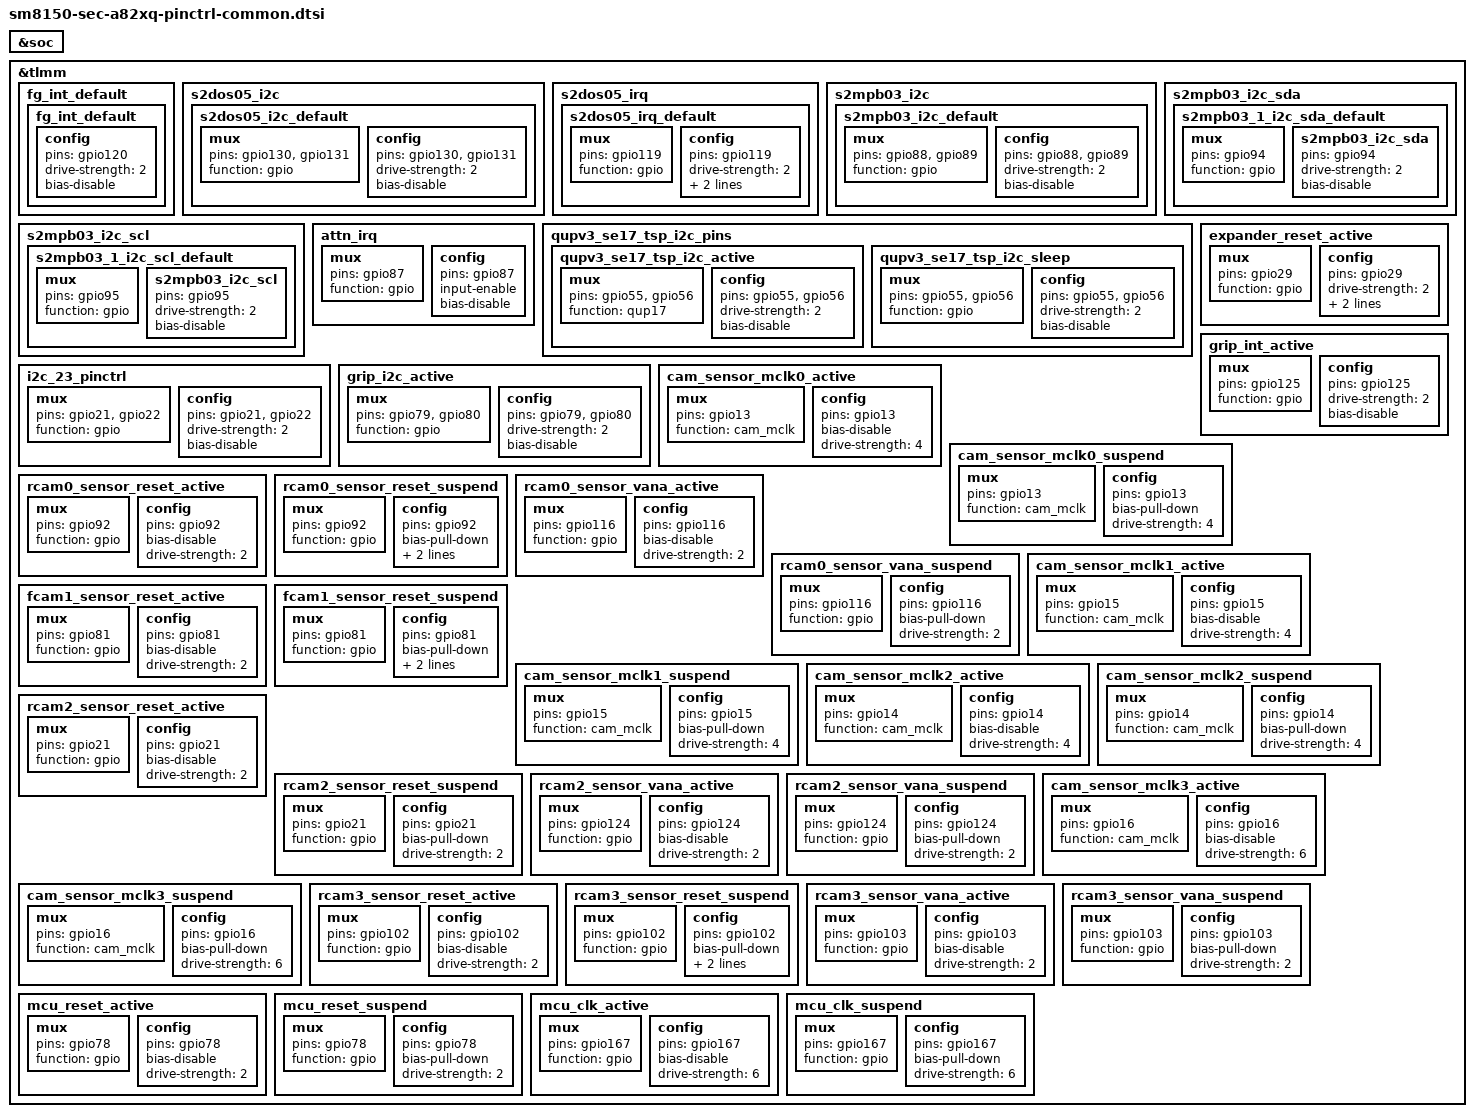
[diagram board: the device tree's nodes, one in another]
/* Copyright (c) 2016-2018, The Linux Foundation. All rights reserved.
 *
 * This program is free software; you can redistribute it and/or modify
 * it under the terms of the GNU General Public License version 2 and
 * only version 2 as published by the Free Software Foundation.
 *
 * This program is distributed in the hope that it will be useful,
 * but WITHOUT ANY WARRANTY; without even the implied warranty of
 * MERCHANTABILITY or FITNESS FOR A PARTICULAR PURPOSE.  See the
 * GNU General Public License for more details.
 */

&soc {
};

&tlmm {
	fg_int_default {
		fg_int_default: fg_int_default {
			config {
				pins = "gpio120";
				drive-strength = <2>;
				bias-disable;
			};
		};
	};

	s2dos05_i2c {
		s2dos05_i2c_default: s2dos05_i2c_default {
			mux {
				pins = "gpio130", "gpio131";
				function = "gpio";
			};

			config {
				pins = "gpio130", "gpio131";
				drive-strength = <2>;
				bias-disable;
			};
		};
	};

	s2dos05_irq {
		s2dos05_irq_default: s2dos05_irq_default {
			mux {
				pins = "gpio119";
				function = "gpio";
			};

			config {
				pins = "gpio119";
				drive-strength = <2>;
				bias-disable;
				input-enable;
			};
		};
	};

	s2mpb03_i2c {
		s2mpb03_i2c_default: s2mpb03_i2c_default {
			mux {
				pins = "gpio88", "gpio89";
				function = "gpio";
			};

			config {
				pins = "gpio88", "gpio89";
				drive-strength = <2>;
				bias-disable;
			};
		};
	};

	s2mpb03_i2c_sda {
		s2mpb03_1_i2c_sda_default: s2mpb03_1_i2c_sda_default {
			mux {
				pins = "gpio94";
				function = "gpio";
			};
			s2mpb03_i2c_sda {
				pins = "gpio94";
				drive-strength = <2>;
				bias-disable;
			};
		};
	};

	s2mpb03_i2c_scl {
		s2mpb03_1_i2c_scl_default: s2mpb03_1_i2c_scl_default {
			mux {
				pins = "gpio95";
				function = "gpio";
			};
			s2mpb03_i2c_scl {
				pins = "gpio95";
				drive-strength = <2>;
				bias-disable;
			};
		};
	};

	attn_irq: attn_irq {
		mux {
			pins = "gpio87";
			function = "gpio";
		};
		config {
			pins = "gpio87";
			input-enable;
			bias-disable;
		};
	};

#if 0
	muic_i2c {
		muic_i2c_active: muic_i2c_active {
			muic_i2c {
				pins = "gpio25", "gpio26";
				drive-strength = <2>;
				bias-disable;
			};
		};
		muic_i2c_suspend: muic_i2c_suspend {
			muic_i2c {
				pins = "gpio25", "gpio26";
				drive-strength = <2>;
				bias-disable;
			};
		};
	};
#endif
	/* SE 17 pin mappings */
	qupv3_se17_tsp_i2c_pins: qupv3_se17_tsp_i2c_pins {
		qupv3_se17_tsp_i2c_active: qupv3_se17_tsp_i2c_active {
			mux {
				pins = "gpio55", "gpio56";
				function = "qup17";
			};

			config {
				pins = "gpio55", "gpio56";
				drive-strength = <2>;
				bias-disable;
			};
		};

		qupv3_se17_tsp_i2c_sleep: qupv3_se17_tsp_i2c_sleep {
			mux {
				pins = "gpio55", "gpio56";
				function = "gpio";
			};

			config {
				pins = "gpio55", "gpio56";
				drive-strength = <2>;
				bias-disable;
			};
		};
	};

	i2c_23_pinctrl: i2c_23_pinctrl {
		mux {
			pins = "gpio21",	/* EXPANDER_I2C_SDA_1P8 */
			       "gpio22";	/* EXPANDER_I2C_SCL_1P8 */
			function = "gpio";
		};
		config {
			pins = "gpio21",	/* EXPANDER_I2C_SDA_1P8 */
			       "gpio22";	/* EXPANDER_I2C_SCL_1P8 */
			drive-strength = <2>;
			bias-disable;
		};
	};

	expander_reset_active: expander_reset_active {
		mux {
			pins = "gpio29";
			function = "gpio";
		};
		config {
			pins = "gpio29";
			drive-strength = <2>;   /* 16 mA */
			bias-disable;
			output-high;
		};
	};

	grip_i2c_active: grip_i2c_active {
		mux {
			pins = "gpio79", "gpio80";
			function = "gpio";
		};
		config {
			pins = "gpio79", "gpio80";
			drive-strength = <2>;
			bias-disable;
		};
	};

	grip_int_active: grip_int_active {
		mux {
			pins = "gpio125";
			function = "gpio";
		};
		config {
			pins = "gpio125";
			drive-strength = <2>;
			bias-disable;
		};
	};

	cam_sensor_mclk0_active: cam_sensor_mclk0_active {
        /* MCLK0 */
        mux {
            pins = "gpio13";
            function = "cam_mclk";
        };
        config {
            pins = "gpio13";
            bias-disable; /* No PULL */
            drive-strength = <4>; /* 4 MA */
        };
    };

    cam_sensor_mclk0_suspend: cam_sensor_mclk0_suspend {
        /* MCLK0 */
        mux {
            pins = "gpio13";
            function = "cam_mclk";
        };
        config {
            pins = "gpio13";
            bias-pull-down; /* PULL DOWN */
            drive-strength = <4>; /* 4 MA */
        };
    };

    rcam0_sensor_reset_active: rcam0_sensor_reset_active {
        /* RESET REAR */
        mux {
            pins = "gpio92";
            function = "gpio";
        };
        config {
            pins = "gpio92";
            bias-disable; /* No PULL */
            drive-strength = <2>; /* 2 MA */
        };
    };

    rcam0_sensor_reset_suspend: rcam0_sensor_reset_suspend {
        /* RESET REAR */
        mux {
            pins = "gpio92";
            function = "gpio";
        };
        config {
            pins = "gpio92";
            bias-pull-down; /* PULL DOWN */
            drive-strength = <2>; /* 2 MA */
            output-low;
        };
    };

    rcam0_sensor_vana_active: rcam0_sensor_vana_active {
        /* Rear VANA */
        mux {
            pins = "gpio116";
            function = "gpio";
        };
        config {
            pins = "gpio116";
            bias-disable; /* No PULL */
            drive-strength = <2>; /* 2 MA */
        };
    };

    rcam0_sensor_vana_suspend: rcam0_sensor_vana_suspend {
        /* Rear VANA */
        mux {
            pins = "gpio116";
            function = "gpio";
        };
        config {
            pins = "gpio116";
            bias-pull-down; /* PULL DOWN */
            drive-strength = <2>; /* 2 MA */
        };
    };
	
    cam_sensor_mclk1_active: cam_sensor_mclk1_active {
        /* MCLK1 */
        mux {
            pins = "gpio15";
            function = "cam_mclk";
        };
        config {
            pins = "gpio15";
            bias-disable; /* No PULL */
            drive-strength = <4>; /* 4 MA */
        };
    };

    fcam1_sensor_reset_active: fcam1_sensor_reset_active {
        /* RESET FRONT */
        mux {
            pins = "gpio81";
            function = "gpio";
        };

        config {
            pins = "gpio81";
            bias-disable; /* No PULL */
            drive-strength = <2>; /* 2 MA */
        };
    };

    fcam1_sensor_reset_suspend: fcam1_sensor_reset_suspend {
        /* RESET FRONT */
        mux {
            pins = "gpio81";
            function = "gpio";
        };

        config {
            pins = "gpio81";
            bias-pull-down; /* PULL DOWN */
            drive-strength = <2>; /* 2 MA */
            output-low;
        };
    };

    cam_sensor_mclk1_suspend: cam_sensor_mclk1_suspend {
        /* MCLK1 */
        mux {
            pins = "gpio15";
            function = "cam_mclk";
        };
        config {
            pins = "gpio15";
            bias-pull-down; /* PULL DOWN */
            drive-strength = <4>; /* 4 MA */
        };
    };

    cam_sensor_mclk2_active: cam_sensor_mclk2_active {
        /* MCLK2 */
        mux {
            pins = "gpio14";
            function = "cam_mclk";
        };

        config {
            pins = "gpio14";
            bias-disable; /* No PULL */
            drive-strength = <4>; /* 4 MA */
        };
    };

    cam_sensor_mclk2_suspend: cam_sensor_mclk2_suspend {
        /* MCLK2 */
        mux {
            pins = "gpio14";
            function = "cam_mclk";
        };

        config {
            pins = "gpio14";
            bias-pull-down; /* PULL DOWN */
            drive-strength = <4>; /* 4 MA */
        };
    };

    rcam2_sensor_reset_active: rcam2_sensor_reset_active {
        /* UW RESET */
        mux {
            pins = "gpio21";
            function = "gpio";
        };
        config {
            pins = "gpio21";
            bias-disable; /* No PULL */
            drive-strength = <2>; /* 2 MA */
        };
    };

    rcam2_sensor_reset_suspend: rcam2_sensor_reset_suspend {
        /* UW RESET */
        mux {
            pins = "gpio21";
            function = "gpio";
        };
        config {
            pins = "gpio21";
            bias-pull-down; /* PULL DOWN */
            drive-strength = <2>; /* 2 MA */
        };
    };

    rcam2_sensor_vana_active: rcam2_sensor_vana_active {
        /* UW VANA */
        mux {
            pins = "gpio124";
            function = "gpio";
        };
        config {
            pins = "gpio124";
            bias-disable; /* No PULL */
            drive-strength = <2>; /* 2 MA */
        };
    };

    rcam2_sensor_vana_suspend: rcam2_sensor_vana_suspend {
        /* UW VANA */
        mux {
            pins = "gpio124";
            function = "gpio";
        };
        config {
            pins = "gpio124";
            bias-pull-down; /* PULL DOWN */
            drive-strength = <2>; /* 2 MA */
        };
    };

    cam_sensor_mclk3_active: cam_sensor_mclk3_active {
        /* MCLK3 */
        mux {
            pins = "gpio16";
            function = "cam_mclk";
        };

        config {
            pins = "gpio16";
            bias-disable; /* No PULL */
            drive-strength = <6>; /* 6 MA */
        };
    };

    cam_sensor_mclk3_suspend: cam_sensor_mclk3_suspend {
        /* MCLK3 */
        mux {
            pins = "gpio16";
            function = "cam_mclk";
        };

        config {
            pins = "gpio16";
            bias-pull-down; /* PULL DOWN */
            drive-strength = <6>; /* 6 MA */
        };
    };

	rcam3_sensor_reset_active: rcam3_sensor_reset_active {
        /* RESET REAR3 */
        mux {
            pins = "gpio102";
            function = "gpio";
        };
        config {
            pins = "gpio102";
            bias-disable; /* No PULL */
            drive-strength = <2>; /* 2 MA */
        };
    };

	rcam3_sensor_reset_suspend: rcam3_sensor_reset_suspend {
        /* RESET REAR3 */
        mux {
            pins = "gpio102";
            function = "gpio";
        };
        config {
            pins = "gpio102";
            bias-pull-down; /* PULL DOWN */
            drive-strength = <2>; /* 2 MA */
            output-low;
        };
    };

    rcam3_sensor_vana_active: rcam3_sensor_vana_active {
        /* Rear3 VANA */
        mux {
            pins = "gpio103";
            function = "gpio";
        };
        config {
            pins = "gpio103";
            bias-disable; /* No PULL */
            drive-strength = <2>; /* 2 MA */
        };
    };

    rcam3_sensor_vana_suspend: rcam3_sensor_vana_suspend {
        /* Rear3 VANA */
        mux {
            pins = "gpio103";
            function = "gpio";
        };
        config {
            pins = "gpio103";
            bias-pull-down; /* PULL DOWN */
            drive-strength = <2>; /* 2 MA */
        };
    };

    mcu_reset_active: mcu_reset_active {
        /* MCU RESET */
        mux {
            pins = "gpio78";
            function = "gpio";
        };
        config {
            pins = "gpio78";
            bias-disable; /* No PULL */
            drive-strength = <2>; /* 2 MA */
        };
    };

    mcu_reset_suspend: mcu_reset_suspend {
        /* MCU RESET */
        mux {
            pins = "gpio78";
            function = "gpio";
        };
        config {
            pins = "gpio78";
            bias-pull-down; /* PULL DOWN */
            drive-strength = <2>; /* 2 MA */
        };
    };

    mcu_clk_active: mcu_clk_active {
        /*  MCU MCLK  */
        mux {
            pins = "gpio167";
            function = "gpio";
        };

        config {
            pins = "gpio167";
            bias-disable; /* No PULL */
            drive-strength = <6>; /* 6 MA */
        };
    };

    mcu_clk_suspend: mcu_clk_suspend {
        /* MCU MCLK */
        mux {
            pins = "gpio167";
            function = "gpio";
        };

        config {
            pins = "gpio167";
            bias-pull-down; /* PULL DOWN */
            drive-strength = <6>; /* 6 MA */
        };
    };
};
